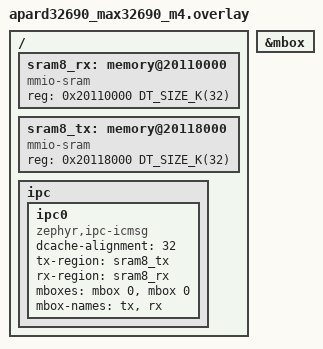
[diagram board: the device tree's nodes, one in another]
/*
 * Copyright (c) 2026 Analog Devices, Inc.
 *
 * SPDX-License-Identifier: Apache-2.0
 */

/ {
	/* Use the upper half of SRAM8 for RX/TX, since the
	 * lower half is reserved for the RV32 core's data
	 */
	sram8_rx: memory@20110000 {
		compatible = "mmio-sram";
		reg = <0x20110000 DT_SIZE_K(32)>;
	};

	sram8_tx: memory@20118000 {
		compatible = "mmio-sram";
		reg = <0x20118000 DT_SIZE_K(32)>;
	};

	ipc {
		ipc0: ipc0 {
			compatible = "zephyr,ipc-icmsg";
			dcache-alignment = <32>;
			tx-region = <&sram8_tx>;
			rx-region = <&sram8_rx>;
			mboxes = <&mbox 0 &mbox 0>;
			mbox-names = "tx", "rx";
			status = "okay";
		};
	};
};

&mbox {
	status = "okay";
};
